# CH32V205 register map
Vendor: WCH Ltd.; File version: 1.0
Registers are 32-bit, read-write, reset 0x0 unless marked. A register's access mark holds for its fields unless they carry their own. Offsets are from the block's base; [hi:lo] are bit positions; {n}, {i} and the like mark numbered series.

## AFIO — Alternate function I/O
Base 0x40010000
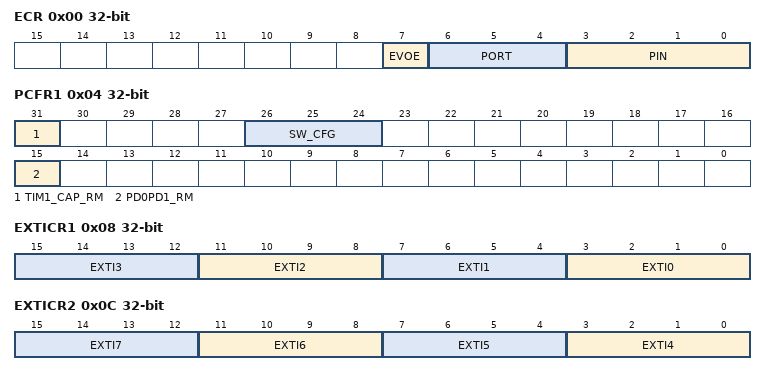
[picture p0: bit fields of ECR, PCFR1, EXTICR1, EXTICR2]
0x00 ECR — Event Control Register (AFIO_ECR)
  [7] EVOE — Event Output Enable
  [6:4] PORT — Port selection
  [3:0] PIN — Pin selection
0x04 PCFR1 access per field — AF remap and debug I/O configuration register 1 (AFIO_PCFR1)
  [31] TIM1_CAP_RM rw — TIM1 channel capture mapping
  [26:24] SW_CFG wo — Serial wire JTAG configuration
  [15] PD0PD1_RM rw — Port D0/Port D1 mapping on OSCIN/OSCOUT
0x08 EXTICR1 — External interrupt configuration register 1 (AFIO_EXTICR1)
  [4n+3:4n] EXTI{n} (n=0..3) — EXTI{n} configuration
0x0C EXTICR2 — External interrupt configuration register 2 (AFIO_EXTICR2)
  [4n-13:4n-16] EXTI{n} (n=4..7) — EXTI{n} configuration
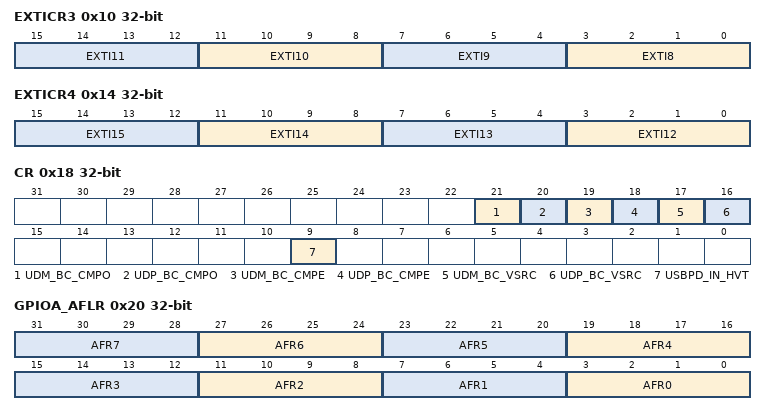
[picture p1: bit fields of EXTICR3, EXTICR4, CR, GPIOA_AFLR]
0x10 EXTICR3 — External interrupt configuration register 3 (AFIO_EXTICR3)
  [4n-29:4n-32] EXTI{n} (n=8..11) — EXTI{n} configuration
0x14 EXTICR4 — External interrupt configuration register 4 (AFIO_EXTICR4)
  [4n-45:4n-48] EXTI{n} (n=12..15) — EXTI{n} configuration
0x18 CR access per field — AFIO control register (AFIO_CR)
  [21] UDM_BC_CMPO ro — PA11/UDM pin BC protocol comparator status
  [20] UDP_BC_CMPO ro — PA12/UDP pin BC protocol comparator status
  [19] UDM_BC_CMPE rw — PA11/UDM pin BC protocol comparator enable
  [18] UDP_BC_CMPE rw — PA12/UDP pin BC protocol comparator enable
  [17] UDM_BC_VSRC rw — PA11/UDM pin BC source voltage enable
  [16] UDP_BC_VSRC rw — PA12/UDP pin BC source voltage enable
  [9] USBPD_IN_HVT rw — PD pin PB6/PD7 High threshold input mode
0x20 GPIOA_AFLR — PA port multiplexing function register
  [4n+3:4n] AFR{n} (n=0..7) — selection of multiplexing function for pin {n} of PA port
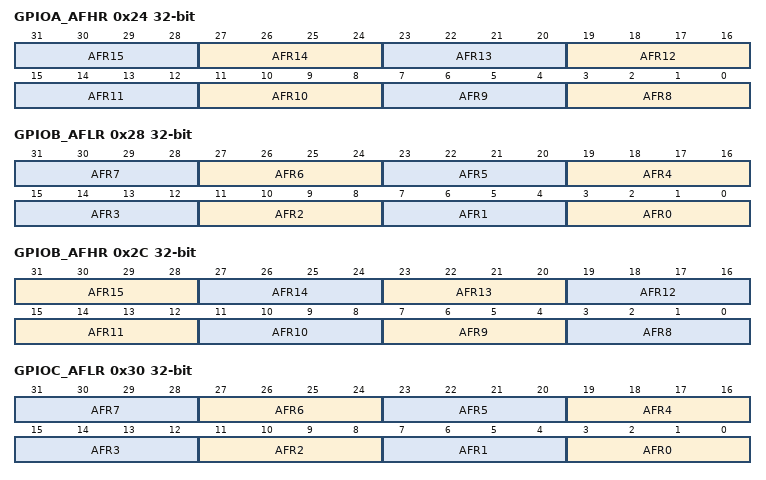
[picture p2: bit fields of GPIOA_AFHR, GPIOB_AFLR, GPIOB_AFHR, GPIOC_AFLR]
0x24 GPIOA_AFHR — PA port multiplexing function register
  [4n-29:4n-32] AFR{n} (n=8..15) — selection of multiplexing function for pin {n} of PA port
0x28 GPIOB_AFLR — PB port multiplexing function register
  [4n+3:4n] AFR{n} (n=0..7) — selection of multiplexing function for pin {n} of PB port
0x2C GPIOB_AFHR — PB port multiplexing function register
  [4n-29:4n-32] AFR{n} (n=9..15) — selection of multiplexing function for pin {n} of PB port
  [3:0] AFR8 — selection of multiplexing function for pin 8 of PA port
0x30 GPIOC_AFLR — PC port multiplexing function register
  [4n+3:4n] AFR{n} (n=0..7) — selection of multiplexing function for pin {n} of PC port
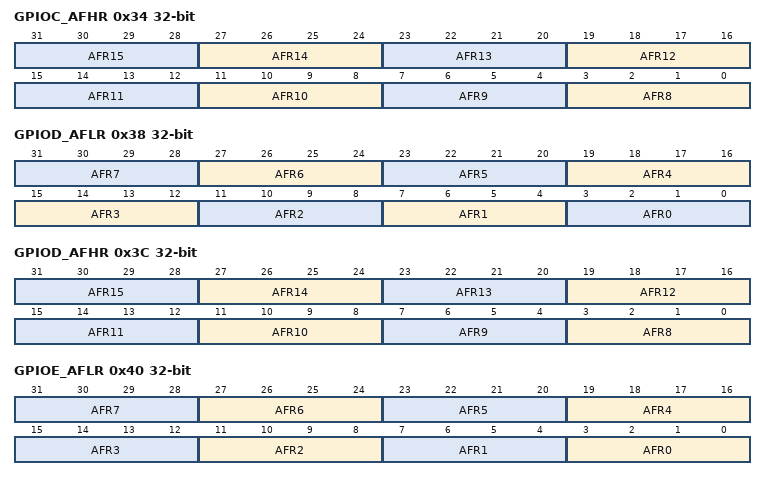
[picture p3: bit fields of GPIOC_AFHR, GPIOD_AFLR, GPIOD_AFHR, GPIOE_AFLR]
0x34 GPIOC_AFHR — PC port multiplexing function register
  [4n-29:4n-32] AFR{n} (n=8..15) — selection of multiplexing function for pin {n} of PC port
0x38 GPIOD_AFLR — PD port multiplexing function register
  [4n+3:4n] AFR{n} (n=4..7) — selection of multiplexing function for pin {n} of PD port
  [15:12] AFR3 — selection of multiplexing function for pin 3 of PA port
  [11:8] AFR2 — selection of multiplexing function for pin 2 of PD port
  [7:4] AFR1 — selection of multiplexing function for pin 1 of PD port
  [3:0] AFR0 — selection of multiplexing function for pin 0 of PD port
0x3C GPIOD_AFHR — PD port multiplexing function register
  [4n-29:4n-32] AFR{n} (n=8..15) — selection of multiplexing function for pin {n} of PD port
0x40 GPIOE_AFLR — PE port multiplexing function register
  [4n+3:4n] AFR{n} (n=0..7) — selection of multiplexing function for pin {n} of PE port
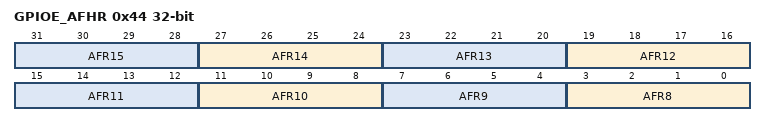
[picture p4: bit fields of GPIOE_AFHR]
0x44 GPIOE_AFHR — PA port multiplexing function register
  [4n-29:4n-32] AFR{n} (n=8..15) — selection of multiplexing function for pin {n} of PE port

## EXTI
Base 0x40010400
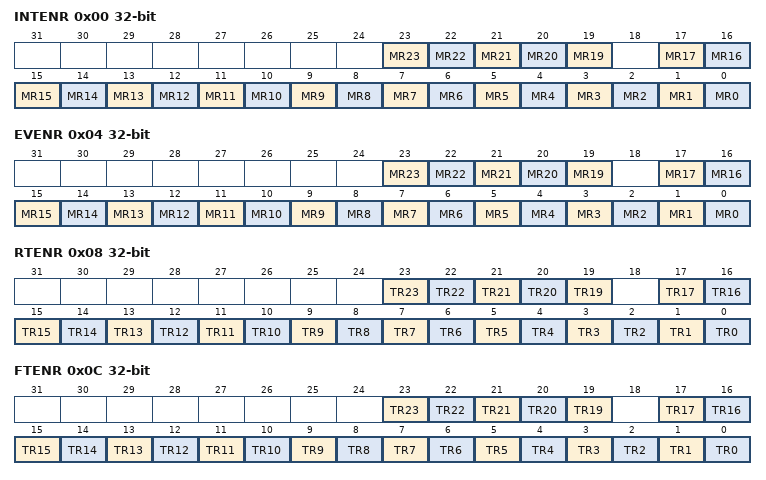
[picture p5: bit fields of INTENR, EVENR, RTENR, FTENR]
0x00 INTENR — Interrupt mask register (EXTI_INTENR)
  [n] MR{n} (n=19..23) — Interrupt Mask on line {n}
  [n] MR{n} (n=0..17) — Interrupt Mask on line {n}
0x04 EVENR — Event mask register (EXTI_EVENR)
  [n] MR{n} (n=19..23) — Event Mask on line {n}
  [n] MR{n} (n=0..17) — Event Mask on line {n}
0x08 RTENR — Rising Trigger selection register (EXTI_RTENR)
  [n] TR{n} (n=19..23) — Rising trigger event configuration of line {n}
  [n] TR{n} (n=0..17) — Rising trigger event configuration of line {n}
0x0C FTENR — Falling Trigger selection register (EXTI_FTENR)
  [n] TR{n} (n=19..23) — Falling trigger event configuration of line {n}
  [n] TR{n} (n=0..17) — Falling trigger event configuration of line {n}
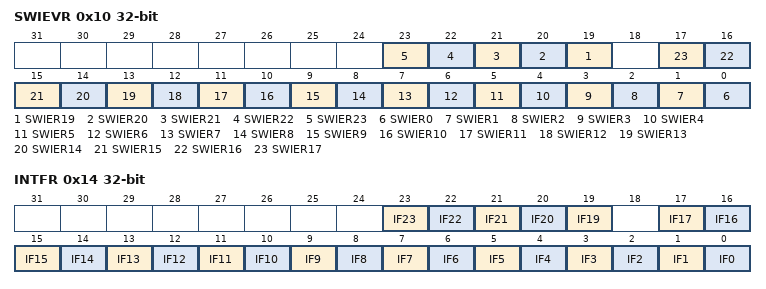
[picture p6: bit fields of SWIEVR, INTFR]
0x10 SWIEVR — Software interrupt event register (EXTI_SWIEVR)
  [n] SWIER{n} (n=19..23) — Software Interrupt on line {n}
  [n] SWIER{n} (n=0..17) — Software Interrupt on line {n}
0x14 INTFR — interrupt flag register (EXTI_INTFR)
  [n] IF{n} (n=19..23) — interrupt flag bit {n}
  [n] IF{n} (n=0..17) — interrupt flag bit {n}
